AUTOSAR XML (schema 4.0)
package /S05FIX/If
  sender receiver interface RemoteCmd
    data val
  sender receiver interface CanFrame
    data val
package /S05FIX/Swc
  application sw component type Telematics
    provide port telToGwOut: provided-interface=RemoteCmd
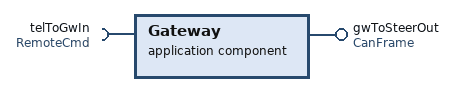
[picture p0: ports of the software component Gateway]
  application sw component type Gateway
    provide port gwToSteerOut: provided-interface=CanFrame
    require port telToGwIn: required-interface=RemoteCmd
  application sw component type SteeringCtrl
    require port gwToSteerIn: required-interface=CanFrame
  composition sw component type Root
    component tel: type=Telematics
    component gw: type=Gateway
    component steer: type=SteeringCtrl
    connect tel.telToGwOut -> gw.telToGwIn
    connect gw.gwToSteerOut -> steer.gwToSteerIn
package /S05FIX/Comm
  pdu telToGwIPdu
    signal telToGwISig: system signal telToGwSSig
  pdu gwToSteerIPdu
    signal gwToSteerISig: system signal gwToSteerSSig
package /S05FIX/Topology
  ecu instance ChassisEcu
  ecu instance GatewayEcu
  ecu instance TelematicsEcu
  system Veh
    root-software-compositions:
      root sw composition prototype Root: software-composition=Root
    system mapping Map
      data-mappings:
        data-element=Root.telToGwOut.val, system-signal=telToGwSSig
        data-element=Root.gwToSteerOut.val, system-signal=gwToSteerSSig
      sw-mappings:
        swc to ecu mapping ToChassisEcu: component=steer, ecu-instance=ChassisEcu
        swc to ecu mapping ToGatewayEcu: component=gw, ecu-instance=GatewayEcu
        swc to ecu mapping ToTelematicsEcu: component=tel, ecu-instance=TelematicsEcu
